# ATSAMA5D27WLSOM1 device description
Architecture: CORTEX-A5; Family: SAMA5; Series: SAMA5D2
Registers are 32-bit, read-write, no defined reset value unless marked. A register's access mark holds for its fields unless they carry their own. Offsets are from the block's base; [hi:lo] are bit positions; {n}, {i} and the like mark numbered series.

## RXLP — Low Power Asynchronous Receiver
Instances: RXLP 0xF8049000
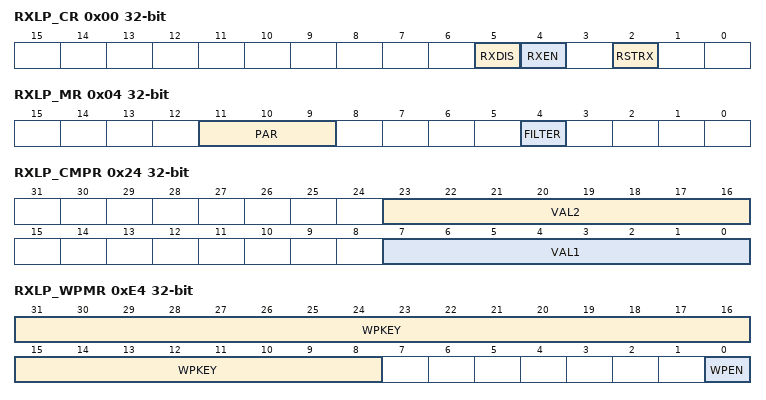
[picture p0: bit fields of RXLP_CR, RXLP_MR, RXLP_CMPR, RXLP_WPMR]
0x00 RXLP_CR wo — Control Register
  [5] RXDIS — Receiver Disable
  [4] RXEN — Receiver Enable
  [2] RSTRX — Reset Receiver
0x04 RXLP_MR — Mode Register
  [11:9] PAR — Parity Type
    0=EVEN (Even Parity); 1=ODD (Odd Parity); 2=SPACE (Parity forced to 0); 3=MARK (Parity forced to 1); 4=NO (No parity)
  [4] FILTER — Receiver Digital Filter
    0=DISABLED (RXLP does not filter the receive line.); 1=ENABLED (RXLP filters the receive line using a three-sample filter (16x-bit clock) (2 over 3 majority).)
0x18 RXLP_RHR ro — Receive Holding Register
  [7:0] RXCHR — Received Character
0x20 RXLP_BRGR — Baud Rate Generator Register
  [1:0] CD — Clock Divisor
0x24 RXLP_CMPR — Comparison Register
  [23:16] VAL2 — Second Comparison Value for Received Character
  [7:0] VAL1 — First Comparison Value for Received Character
0xE4 RXLP_WPMR — Write Protection Mode Register
  [31:8] WPKEY — Write Protection Key
    0x52584C=PASSWD (Writing any other value in this field aborts the write operation.Always reads as 0.)
  [0] WPEN — Write Protection Enable

## SCKC — Slow Clock Controller
Instances: SCKC 0xF8048050
0x00 SCKC_CR — Slow Clock Controller Configuration Register
  [3] OSCSEL — Slow Clock Selector
    0=RC (Slow clock is the embedded 64 kHz (typical) RC oscillator.); 1=XTAL (Slow clock is the 32.768 kHz crystal oscillator.)

## SECUMOD — Security Module
Instances: SECUMOD 0xFC040000
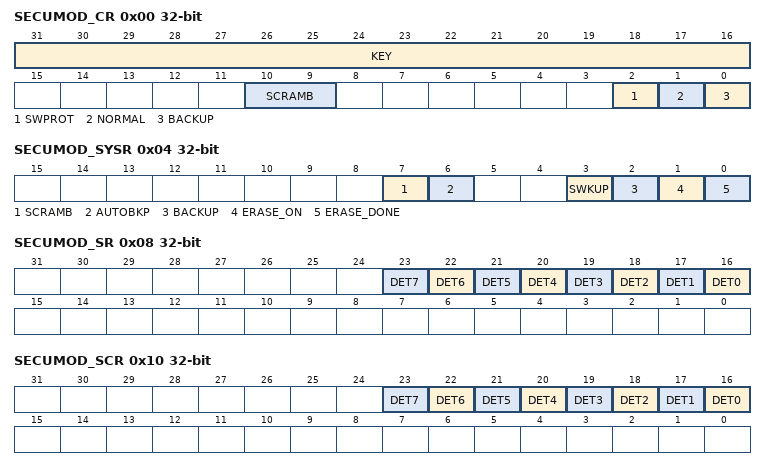
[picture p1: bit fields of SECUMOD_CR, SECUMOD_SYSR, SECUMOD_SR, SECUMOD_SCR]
0x00 SECUMOD_CR wo — Control Register
  [31:16] KEY — Password
  [10:9] SCRAMB — Memory Scrambling Enable
  [2] SWPROT — Software Protection
  [1] NORMAL — Normal Mode
  [0] BACKUP — Backup Mode
0x04 SECUMOD_SYSR — System Status Register
  [7] SCRAMB — Scrambling Enabled (RO)
  [6] AUTOBKP — Automatic Backup Mode Enabled (RO)
  [3] SWKUP — SWKUP State (RO)
  [2] BACKUP — Backup Mode (RO)
  [1] ERASE_ON — Erase Process Ongoing (RO)
  [0] ERASE_DONE — Erasable Memories State (RW)
0x08 SECUMOD_SR ro — Status Register
  [n+16] DET{n} (n=0..7) — PIOBU Intrusion Detector
0x10 SECUMOD_SCR wo — Status Clear Register
  [n+16] DET{n} (n=0..7) — PIOBU Intrusion Detector
0x14 SECUMOD_RAMRDY ro — RAM Access Ready Register
  [0] READY — Ready for system access flag
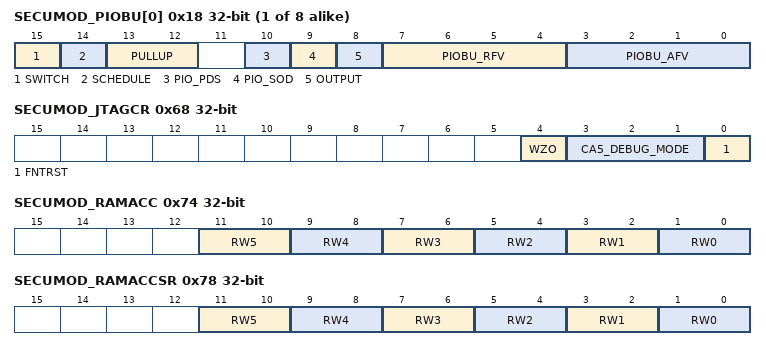
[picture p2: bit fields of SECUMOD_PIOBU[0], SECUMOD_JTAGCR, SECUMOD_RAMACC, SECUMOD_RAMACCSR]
{0x18+4i} SECUMOD_PIOBU[{i}] (i=0..7) — PIO Backup Register
  [15] SWITCH — Switch State for Intrusion Detection
  [14] SCHEDULE — Pull-up/Down Scheduled
  [13:12] PULLUP — Programmable Pull-up State
  [10] PIO_PDS — Level on the Pin in Input Mode (OUTPUT = 0) (Read-only)
  [9] PIO_SOD — Set/Clear the I/O Line when configured in Output Mode (OUTPUT =1)
  [8] OUTPUT — Configure I/O Line in Input/Output
  [7:4] PIOBU_RFV — PIOBUx Reset Filter Value
  [3:0] PIOBU_AFV — PIOBU Alarm Filter Value
0x68 SECUMOD_JTAGCR — JTAG Protection Control Register
  [4] WZO — Write ZERO
  [3:1] CA5_DEBUG_MODE — Cortex-A5 Invasive/Non-Invasive Secure/Non-Secure Debug Permissions
  [0] FNTRST — Force NTRST
0x70 SECUMOD_SCRKEY — Scrambling Key Register
  [31:0] SCRKEY — Scrambling Key Value
0x74 SECUMOD_RAMACC — RAM Access Rights Register
  [11:10] RW5 — Access right for RAM region [5 Kbytes; 6 Kbytes] (register bank BUREG256b)
  [9:8] RW4 — Access right for RAM region [4 Kbytes; 5 Kbytes]
  [7:6] RW3 — Access right for RAM region [3 Kbytes; 4 Kbytes]
  [5:4] RW2 — Access right for RAM region [2 Kbytes; 3 Kbytes]
  [3:2] RW1 — Access right for RAM region [1 Kbyte; 2 Kbytes]
  [1:0] RW0 — Access right for RAM region [0; 1 Kbyte]
0x78 SECUMOD_RAMACCSR — RAM Access Rights Status Register
  [11:10] RW5 — Access right status for RAM region [5 Kbytes; 6 Kbytes] (register bank BUREG256b)
  [9:8] RW4 — Access right status for RAM region [4 Kbytes; 5 Kbytes]
  [7:6] RW3 — Access right status for RAM region [3 Kbytes; 4 Kbytes]
  [5:4] RW2 — Access right status for RAM region [2 Kbytes; 3 Kbytes]
  [3:2] RW1 — Access right status for RAM region [1 Kbytes; 2 Kbytes]
  [1:0] RW0 — Access right status for RAM region [0; 1 Kbyte]
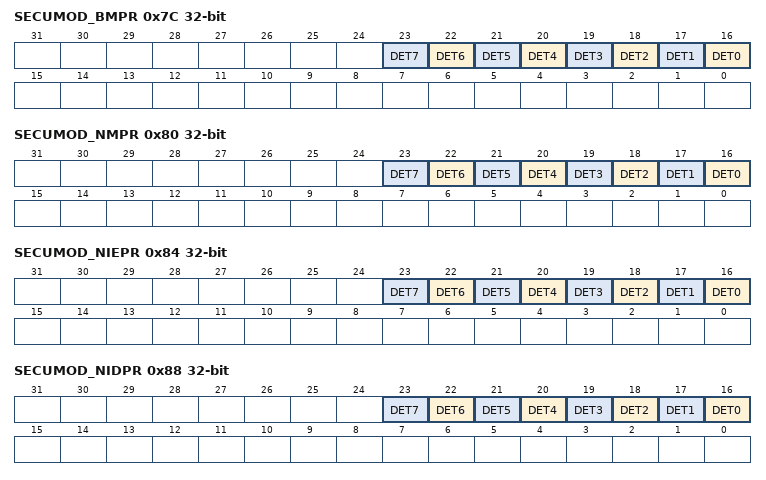
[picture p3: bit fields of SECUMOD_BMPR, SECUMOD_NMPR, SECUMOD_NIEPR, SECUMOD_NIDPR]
0x7C SECUMOD_BMPR — Backup Mode Protection Register
  [n+16] DET{n} (n=0..7) — PIOBU Intrusion Detector Protection
0x80 SECUMOD_NMPR — Normal Mode Protection Register
  [n+16] DET{n} (n=0..7) — PIOBU Intrusion Detector Protection
0x84 SECUMOD_NIEPR wo — Normal Interrupt Enable Protection Register
  [n+16] DET{n} (n=0..7) — PIOBU Intrusion Detector Protection Interrupt Enable
0x88 SECUMOD_NIDPR wo — Normal Interrupt Disable Protection Register
  [n+16] DET{n} (n=0..7) — PIOBU Intrusion Detector Protection Interrupt Disable
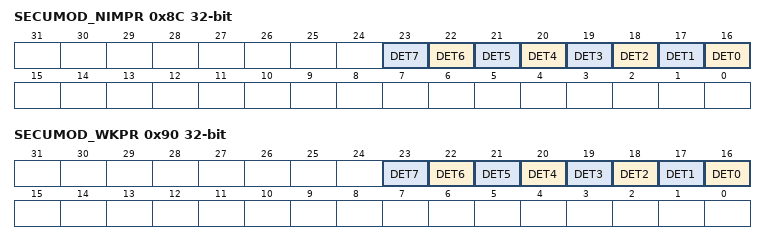
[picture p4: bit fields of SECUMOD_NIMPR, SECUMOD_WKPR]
0x8C SECUMOD_NIMPR ro — Normal Interrupt Mask Protection Register
  [n+16] DET{n} (n=0..7) — PIOBU Intrusion Detector Protection Interrupt Mask
0x90 SECUMOD_WKPR — Wakeup Protection Register
  [n+16] DET{n} (n=0..7) — PIOBU Intrusion Detector Protection
